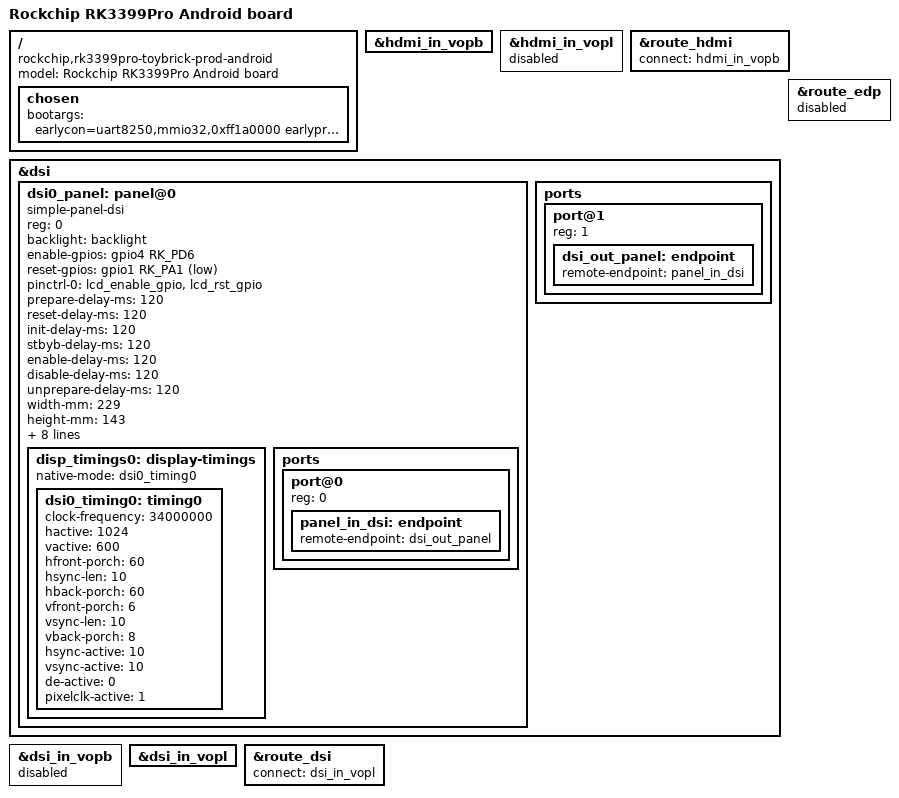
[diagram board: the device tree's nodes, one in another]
/dts-v1/;
#include "rk3399pro-amolk.dtsi"
#include "rk3399-android.dtsi"

/ {
	compatible = "rockchip,rk3399pro-toybrick-prod-android", "rockchip,rk3399pro";
	model = "Rockchip RK3399Pro Android board";

	chosen {
		bootargs = "earlycon=uart8250,mmio32,0xff1a0000 earlyprintk loglevel=7 swiotlb=1 console=ttyFIQ0 androidboot.baseband=N/A androidboot.veritymode=enforcing androidboot.hardware=rk30board androidboot.console=ttyFIQ0 init=/init initrd=0x62000000,0x00800000 coherent_pool=1m";
	};
};

&hdmi_in_vopb {
	status = "okay";
};

&hdmi_in_vopl {
	status = "disabled";
};

&route_hdmi {
	status = "okay";
	connect = <&hdmi_in_vopb>;
};

&dsi {
	status = "okay";

    dsi0_panel: panel@0 {
        status = "okay";
        compatible = "simple-panel-dsi";
        reg = <0>;
        backlight = <&backlight>;
        enable-gpios = <&gpio4 RK_PD6 GPIO_ACTIVE_HIGH>;
        reset-gpios = <&gpio1 RK_PA1 GPIO_ACTIVE_LOW>;

        pinctrl-names = "default";
        pinctrl-0 = <&lcd_enable_gpio>, <&lcd_rst_gpio>;
        prepare-delay-ms = <120>;
        reset-delay-ms = <120>;
        init-delay-ms = <120>;
        stbyb-delay-ms = <120>;
        enable-delay-ms = <120>;
        disable-delay-ms = <120>;
        unprepare-delay-ms = <120>;
        width-mm = <229>;
        height-mm = <143>;
        dsi,flags = <(MIPI_DSI_MODE_VIDEO | MIPI_DSI_MODE_VIDEO_BURST |
            MIPI_DSI_MODE_LPM | MIPI_DSI_MODE_EOT_PACKET)>;
        dsi,format = <MIPI_DSI_FMT_RGB888>;
        dsi,lanes  = <4>;
        panel-init-sequence = [
            15 00 02 80 AC
            15 00 02 81 B8
            15 00 02 82 09
            15 00 02 83 78
            15 00 02 84 7F
            15 00 02 85 BB
            15 00 02 86 70
            05 78 01 11
            05 1E 01 29
        ];
        panel-exit-sequence = [
            05 00 01 28
            05 00 01 10
        ];

        disp_timings0: display-timings {
            native-mode = <&dsi0_timing0>;
            dsi0_timing0: timing0 {
                clock-frequency = <34000000>;
                hactive = <1024>;
                vactive = <600>;
                hfront-porch = <60>;
                hsync-len = <10>;
                hback-porch = <60>;
                vfront-porch = <6>;
                vsync-len = <10>;
                vback-porch = <8>;
                hsync-active = <10>;
                vsync-active = <10>;
                de-active = <0>;
                pixelclk-active = <1>;
            };
        };

        ports {
            #address-cells = <1>;
            #size-cells = <0>;

            port@0 {
                reg = <0>;
                panel_in_dsi: endpoint {
                    remote-endpoint = <&dsi_out_panel>;
                };
            };
        };
    };

    ports {
        #address-cells = <1>;
        #size-cells = <0>;

        port@1 {
            reg = <1>;
            dsi_out_panel: endpoint {
                remote-endpoint = <&panel_in_dsi>;
            };
        };
    };
};

&dsi_in_vopb {
	status = "disabled";
};

&dsi_in_vopl {
	status = "okay";
};

&route_dsi {
	status = "okay";
	connect = <&dsi_in_vopl>;
};

&route_edp {
	status = "disabled";
};
